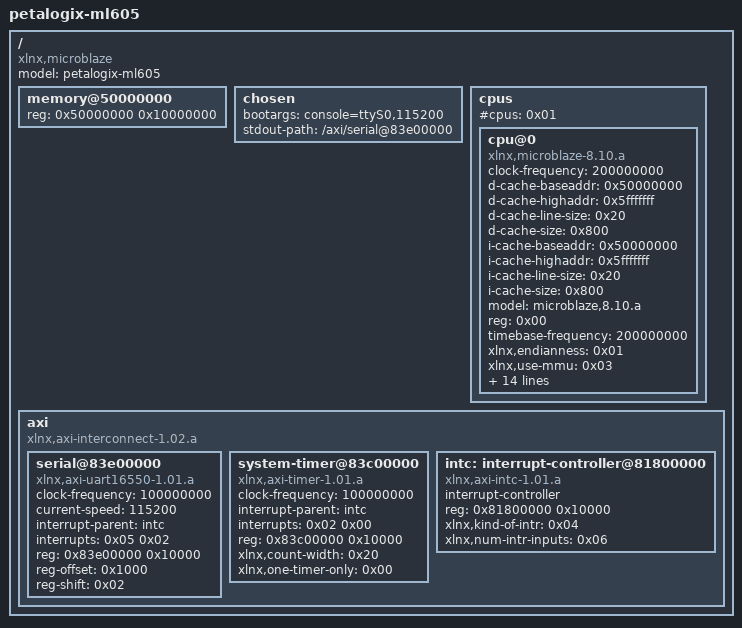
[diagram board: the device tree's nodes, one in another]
/dts-v1/;

/ {
	#address-cells = <0x01>;
	#size-cells = <0x01>;
	compatible = "xlnx,microblaze";
	model = "petalogix-ml605";

	memory@50000000 {
		device_type = "memory";
		reg = <0x50000000 0x10000000>;
	};

	chosen {
		bootargs = "console=ttyS0,115200";
		stdout-path = "/axi/serial@83e00000";
	};

	cpus {
		#address-cells = <0x01>;
		#cpus = <0x01>;
		#size-cells = <0x00>;

		cpu@0 {
			clock-frequency = <200000000>;
			compatible = "xlnx,microblaze-8.10.a";
			d-cache-baseaddr = <0x50000000>;
			d-cache-highaddr = <0x5fffffff>;
			d-cache-line-size = <0x20>;
			d-cache-size = <0x800>;
			device_type = "cpu";
			i-cache-baseaddr = <0x50000000>;
			i-cache-highaddr = <0x5fffffff>;
			i-cache-line-size = <0x20>;
			i-cache-size = <0x800>;
			model = "microblaze,8.10.a";
			reg = <0x00>;
			timebase-frequency = <200000000>;
			xlnx,endianness = <0x01>;
			xlnx,use-mmu = <0x03>;
			xlnx,use-barrel = <0x01>;
			xlnx,use-div = <0x01>;
			xlnx,use-hw-mul = <0x02>;
			xlnx,use-fpu = <0x01>;
			xlnx,use-msr-instr = <0x01>;
			xlnx,use-pcmp-instr = <0x01>;
			xlnx,pvr = <0x02>;
			xlnx,use-dcache = <0x01>;
			xlnx,use-icache = <0x01>;
			xlnx,mmu-dtlb-size = <0x04>;
			xlnx,mmu-itlb-size = <0x02>;
			xlnx,mmu-tlb-access = <0x03>;
			xlnx,mmu-zones = <0x02>;
			xlnx,use-interrupt = <0x01>;
		};
	};

	axi {
		#address-cells = <0x01>;
		#size-cells = <0x01>;
		compatible = "xlnx,axi-interconnect-1.02.a", "simple-bus";
		ranges;

		serial@83e00000 {
			clock-frequency = <100000000>;
			compatible = "xlnx,axi-uart16550-1.01.a", "xlnx,xps-uart16550-2.00.a", "ns16550a";
			current-speed = <115200>;
			device_type = "serial";
			interrupt-parent = <&intc>;
			interrupts = <0x05 0x02>;
			reg = <0x83e00000 0x10000>;
			reg-offset = <0x1000>;
			reg-shift = <0x02>;
		};

		system-timer@83c00000 {
			clock-frequency = <100000000>;
			compatible = "xlnx,axi-timer-1.01.a", "xlnx,xps-timer-1.00.a";
			interrupt-parent = <&intc>;
			interrupts = <0x02 0x00>;
			reg = <0x83c00000 0x10000>;
			xlnx,count-width = <0x20>;
			xlnx,one-timer-only = <0x00>;
		};

		intc: interrupt-controller@81800000 {
			#interrupt-cells = <0x02>;
			compatible = "xlnx,axi-intc-1.01.a", "xlnx,xps-intc-1.00.a";
			interrupt-controller;
			reg = <0x81800000 0x10000>;
			xlnx,kind-of-intr = <0x04>;
			xlnx,num-intr-inputs = <0x06>;
		};
	};
};
